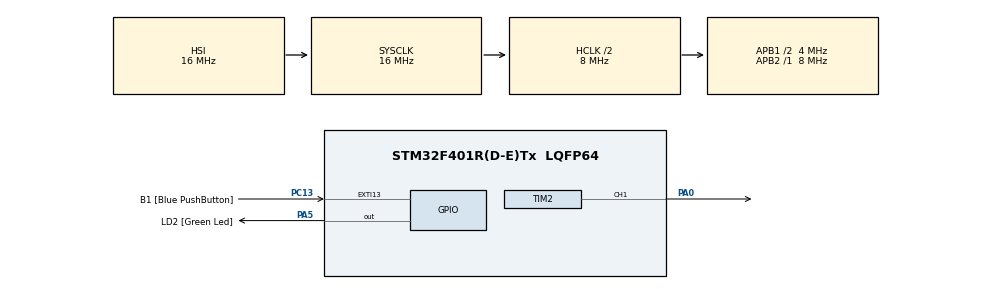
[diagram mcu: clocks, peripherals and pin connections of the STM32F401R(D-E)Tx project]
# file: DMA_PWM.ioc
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Mcu.Family=STM32F4
PA2.GPIO_PuPd=GPIO_NOPULL
Dma.TIM2_CH1.0.MemInc=DMA_MINC_ENABLE
RCC.CortexFreq_Value=8000000
PC13-ANTI_TAMP.GPIO_PuPd=GPIO_NOPULL
PC13-ANTI_TAMP.GPIO_Label=B1 [Blue PushButton]
PA14.GPIO_Label=TCK
PA3.GPIO_PuPd=GPIO_NOPULL
PA2.GPIO_Speed=GPIO_SPEED_FREQ_LOW
Dma.TIM2_CH1.0.Instance=DMA1_Stream5
RCC.APB1CLKDivider=RCC_HCLK_DIV2
PC14-OSC32_IN.Signal=RCC_OSC32_IN
PA3.GPIO_Speed=GPIO_SPEED_FREQ_LOW
ProjectManager.StackSize=0x400
PA0-WKUP.Signal=S_TIM2_CH1_ETR
TIM2.Pulse-PWM\ Generation1\ CH1=500
PA13.Signal=SYS_JTMS-SWDIO
PH0\ -\ OSC_IN.Signal=RCC_OSC_IN
ProjectManager.TargetToolchain=STM32CubeIDE
NVIC.DMA1_Stream5_IRQn=true\:0\:0\:false\:false\:true\:false\:true
PA3.GPIO_Mode=GPIO_MODE_AF_PP
RCC.HCLKFreq_Value=8000000
RCC.APB2TimFreq_Value=8000000
PC15-OSC32_OUT.Signal=RCC_OSC32_OUT
RCC.AHBFreq_Value=8000000
PA5.Signal=GPIO_Output
RCC.HSE_VALUE=8000000
PH1\ -\ OSC_OUT.Signal=RCC_OSC_OUT
board=NUCLEO-F401RE
PC13-ANTI_TAMP.Signal=GPXTI13
RCC.VCOOutputFreq_Value=336000000
RCC.APB2Freq_Value=8000000
Dma.TIM2_CH1.0.Priority=DMA_PRIORITY_LOW
PA14.Mode=Serial_Wire
PA5.GPIO_PuPd=GPIO_NOPULL
RCC.AHBCLKDivider=RCC_SYSCLK_DIV2
TIM2.Channel-PWM\ Generation1\ CH1=TIM_CHANNEL_1
TIM2.Period=999
PA13.Mode=Serial_Wire
Mcu.Name=STM32F401R(D-E)Tx
PA2.Signal=USART2_TX
PA13.GPIO_Label=TMS
RCC.48MHZClocksFreq_Value=48000000
PB3.Signal=SYS_JTDO-SWO
RCC.SYSCLKFreq_VALUE=16000000
Mcu.Package=LQFP64
Dma.TIM2_CH1.0.Mode=DMA_NORMAL
TIM2.Prescaler=7
Dma.TIM2_CH1.0.FIFOMode=DMA_FIFOMODE_DISABLE
PA5.GPIO_Label=LD2 [Green Led]
PC13-ANTI_TAMP.GPIO_ModeDefaultEXTI=GPIO_MODE_IT_FALLING
PA2.GPIO_Label=USART_TX
Dma.TIM2_CH1.0.MemDataAlignment=DMA_MDATAALIGN_WORD
SH.S_TIM2_CH1_ETR.0=TIM2_CH1,PWM Generation1 CH1
PA14.Signal=SYS_JTCK-SWCLK
ProjectManager.HeapSize=0x200
Dma.TIM2_CH1.0.PeriphDataAlignment=DMA_PDATAALIGN_WORD
RCC.HSI_VALUE=16000000
RCC.PLLP=RCC_PLLP_DIV4
PA5.GPIO_Speed=GPIO_SPEED_FREQ_LOW
RCC.PLLQ=7
NVIC.PriorityGroup=NVIC_PRIORITYGROUP_0
RCC.PLLN=336
RCC.APB1TimFreq_Value=8000000
TIM2.AutoReloadPreload=TIM_AUTORELOAD_PRELOAD_ENABLE
Dma.Request0=TIM2_CH1
RCC.APB1Freq_Value=4000000
PA5.GPIO_Mode=GPIO_MODE_OUTPUT_PP
Dma.TIM2_CH1.0.Direction=DMA_MEMORY_TO_PERIPH
Dma.TIM2_CH1.0.PeriphInc=DMA_PINC_DISABLE
PA3.GPIO_Label=USART_RX
PA3.Signal=USART2_RX
PA2.GPIO_Mode=GPIO_MODE_AF_PP
PB3.GPIO_Label=SWO

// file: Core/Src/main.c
/* USER CODE BEGIN Header */
/**
  ******************************************************************************
  * @file           : main.c
  * @brief          : Main program body
  ******************************************************************************
  * @attention
  *
  * <h2><center>&copy; Copyright (c) 2021 STMicroelectronics.
  * All rights reserved.</center></h2>
  *
  * This software component is licensed by ST under BSD 3-Clause license,
  * the "License"; You may not use this file except in compliance with the
  * License. You may obtain a copy of the License at:
  *                        opensource.org/licenses/BSD-3-Clause
  *
  ******************************************************************************
  */
/* USER CODE END Header */
#include "main.h"

/* USER CODE BEGIN Includes */
#include <math.h>

/* USER CODE END Includes */

/* USER CODE BEGIN PD */
#define ARRAY_SIZE 1000
/* USER CODE END PD */

TIM_HandleTypeDef htim2;
DMA_HandleTypeDef hdma_tim2_ch1;

/* USER CODE BEGIN PV */
uint32_t ssin[ARRAY_SIZE] = {0};

/* USER CODE END PV */

void SystemClock_Config(void);
static void MX_GPIO_Init(void);
static void MX_DMA_Init(void);
static void MX_TIM2_Init(void);

int main(void)
{

  /* MCU Configuration--------------------------------------------------------*/

  /* Reset of all peripherals, Initializes the Flash interface and the Systick. */
  HAL_Init();

  /* Configure the system clock */
  SystemClock_Config();

  /* Initialize all configured peripherals */
  MX_GPIO_Init();
  MX_DMA_Init();
  MX_TIM2_Init();
  /* USER CODE BEGIN 2 */
  for(uint16_t i=0;i<ARRAY_SIZE;i++) {
  	        //array[i] = (sin(M_PI * i / ARRAY_SIZE)) * 1000;
  	        ssin[i] = (sin(M_PI*i/(ARRAY_SIZE-1))) * (htim2.Init.Period + 1);
  	}
  HAL_TIM_PWM_Start_DMA(&htim2, TIM_CHANNEL_1, ssin, ARRAY_SIZE);

  /* USER CODE END 2 */

  /* Infinite loop */
  while (1)
  {

  }
}

void SystemClock_Config(void)
{
  RCC_OscInitTypeDef RCC_OscInitStruct = {0};
  RCC_ClkInitTypeDef RCC_ClkInitStruct = {0};

  /** Configure the main internal regulator output voltage
  */
  __HAL_RCC_PWR_CLK_ENABLE();
  __HAL_PWR_VOLTAGESCALING_CONFIG(PWR_REGULATOR_VOLTAGE_SCALE2);
  /** Initializes the RCC Oscillators according to the specified parameters
  * in the RCC_OscInitTypeDef structure.
  */
  RCC_OscInitStruct.OscillatorType = RCC_OSCILLATORTYPE_HSI;
  RCC_OscInitStruct.HSIState = RCC_HSI_ON;
  RCC_OscInitStruct.HSICalibrationValue = RCC_HSICALIBRATION_DEFAULT;
  RCC_OscInitStruct.PLL.PLLState = RCC_PLL_NONE;
  if (HAL_RCC_OscConfig(&RCC_OscInitStruct) != HAL_OK)
  {
    Error_Handler();
  }
  /** Initializes the CPU, AHB and APB buses clocks
  */
  RCC_ClkInitStruct.ClockType = RCC_CLOCKTYPE_HCLK|RCC_CLOCKTYPE_SYSCLK
                              |RCC_CLOCKTYPE_PCLK1|RCC_CLOCKTYPE_PCLK2;
  RCC_ClkInitStruct.SYSCLKSource = RCC_SYSCLKSOURCE_HSI;
  RCC_ClkInitStruct.AHBCLKDivider = RCC_SYSCLK_DIV2;
  RCC_ClkInitStruct.APB1CLKDivider = RCC_HCLK_DIV2;
  RCC_ClkInitStruct.APB2CLKDivider = RCC_HCLK_DIV1;

  if (HAL_RCC_ClockConfig(&RCC_ClkInitStruct, FLASH_LATENCY_0) != HAL_OK)
  {
    Error_Handler();
  }
}

static void MX_TIM2_Init(void)
{

  TIM_MasterConfigTypeDef sMasterConfig = {0};
  TIM_OC_InitTypeDef sConfigOC = {0};

  htim2.Instance = TIM2;
  htim2.Init.Prescaler = 7;
  htim2.Init.CounterMode = TIM_COUNTERMODE_UP;
  htim2.Init.Period = 999;
  htim2.Init.ClockDivision = TIM_CLOCKDIVISION_DIV1;
  htim2.Init.AutoReloadPreload = TIM_AUTORELOAD_PRELOAD_ENABLE;
  if (HAL_TIM_PWM_Init(&htim2) != HAL_OK)
  {
    Error_Handler();
  }
  sMasterConfig.MasterOutputTrigger = TIM_TRGO_RESET;
  sMasterConfig.MasterSlaveMode = TIM_MASTERSLAVEMODE_DISABLE;
  if (HAL_TIMEx_MasterConfigSynchronization(&htim2, &sMasterConfig) != HAL_OK)
  {
    Error_Handler();
  }
  sConfigOC.OCMode = TIM_OCMODE_PWM1;
  sConfigOC.Pulse = 500;
  sConfigOC.OCPolarity = TIM_OCPOLARITY_HIGH;
  sConfigOC.OCFastMode = TIM_OCFAST_DISABLE;
  if (HAL_TIM_PWM_ConfigChannel(&htim2, &sConfigOC, TIM_CHANNEL_1) != HAL_OK)
  {
    Error_Handler();
  }
  HAL_TIM_MspPostInit(&htim2);

}

static void MX_DMA_Init(void)
{

  /* DMA controller clock enable */
  __HAL_RCC_DMA1_CLK_ENABLE();

  /* DMA interrupt init */
  /* DMA1_Stream5_IRQn interrupt configuration */
  HAL_NVIC_SetPriority(DMA1_Stream5_IRQn, 0, 0);
  HAL_NVIC_EnableIRQ(DMA1_Stream5_IRQn);

}

static void MX_GPIO_Init(void)
{
  GPIO_InitTypeDef GPIO_InitStruct = {0};

  /* GPIO Ports Clock Enable */
  __HAL_RCC_GPIOC_CLK_ENABLE();
  __HAL_RCC_GPIOH_CLK_ENABLE();
  __HAL_RCC_GPIOA_CLK_ENABLE();
  __HAL_RCC_GPIOB_CLK_ENABLE();

  /*Configure GPIO pin Output Level */
  HAL_GPIO_WritePin(LD2_GPIO_Port, LD2_Pin, GPIO_PIN_RESET);

  /*Configure GPIO pin : B1_Pin */
  GPIO_InitStruct.Pin = B1_Pin;
  GPIO_InitStruct.Mode = GPIO_MODE_IT_FALLING;
  GPIO_InitStruct.Pull = GPIO_NOPULL;
  HAL_GPIO_Init(B1_GPIO_Port, &GPIO_InitStruct);

  /*Configure GPIO pins : USART_TX_Pin USART_RX_Pin */
  GPIO_InitStruct.Pin = USART_TX_Pin|USART_RX_Pin;
  GPIO_InitStruct.Mode = GPIO_MODE_AF_PP;
  GPIO_InitStruct.Pull = GPIO_NOPULL;
  GPIO_InitStruct.Speed = GPIO_SPEED_FREQ_LOW;
  GPIO_InitStruct.Alternate = GPIO_AF7_USART2;
  HAL_GPIO_Init(GPIOA, &GPIO_InitStruct);

  /*Configure GPIO pin : LD2_Pin */
  GPIO_InitStruct.Pin = LD2_Pin;
  GPIO_InitStruct.Mode = GPIO_MODE_OUTPUT_PP;
  GPIO_InitStruct.Pull = GPIO_NOPULL;
  GPIO_InitStruct.Speed = GPIO_SPEED_FREQ_LOW;
  HAL_GPIO_Init(LD2_GPIO_Port, &GPIO_InitStruct);

}

/* USER CODE BEGIN 4 */
void HAL_TIM_PWM_PulseFinishedCallback(TIM_HandleTypeDef *htim)
{
	HAL_TIM_PWM_Start_DMA(&htim2, TIM_CHANNEL_1, ssin, ARRAY_SIZE);
}

/* USER CODE END 4 */

void Error_Handler(void)
{
  __disable_irq();
  while (1)
  {
  }
}

/************************ (C) COPYRIGHT STMicroelectronics *****END OF FILE****/
